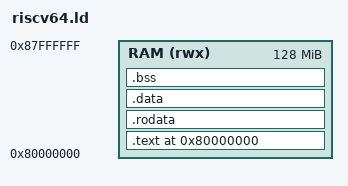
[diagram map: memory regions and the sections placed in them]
ENTRY(_start)
MEMORY {
    RAM (rwx) : ORIGIN = 0x80000000, LENGTH = 128M
}
SECTIONS {
    . = 0x80000000;

    .text : {
        *(.text.init)
        *(.text .text.*)
    } > RAM

    .rodata : {
        *(.rodata .rodata.*)
    } > RAM

    .data : {
        *(.data .data.*)
    } > RAM

    .bss (NOLOAD) : {
        __bss_start = .;
        *(.bss .bss.*)
        *(COMMON)
        __bss_end = .;
    } > RAM

    . = ALIGN(16);
    __stack_top = . + 64K;
}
